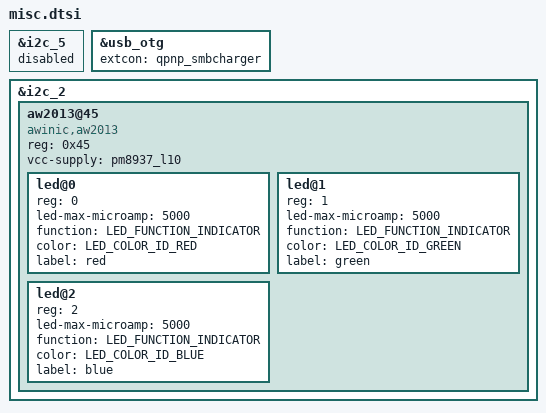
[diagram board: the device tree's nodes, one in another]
#include <dt-bindings/leds/common.h>

&i2c_5 {
	status = "disabled";
};

&usb_otg {
	extcon = <&qpnp_smbcharger>;
};

&i2c_2 {
	status = "ok";
	aw2013@45 {
		#address-cells = <1>;
		#size-cells = <0>;

		compatible = "awinic,aw2013";

		reg = <0x45>;
		vcc-supply = <&pm8937_l10>;

		led@0 {
			reg = <0>;
			led-max-microamp = <5000>;
			function = LED_FUNCTION_INDICATOR;
			color = <LED_COLOR_ID_RED>;
			label = "red";
		};
		led@1 {
			reg = <1>;
			led-max-microamp = <5000>;
			function = LED_FUNCTION_INDICATOR;
			color = <LED_COLOR_ID_GREEN>;
			label = "green";
		};
		led@2 {
			reg = <2>;
			led-max-microamp = <5000>;
			function = LED_FUNCTION_INDICATOR;
			color = <LED_COLOR_ID_BLUE>;
			label = "blue";
		};
	};
};
